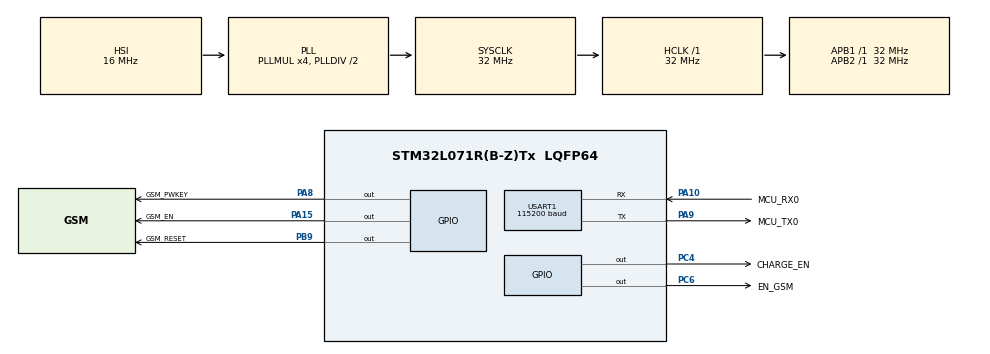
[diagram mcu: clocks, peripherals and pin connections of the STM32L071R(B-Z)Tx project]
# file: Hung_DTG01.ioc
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Mcu.Family=STM32L0
Mcu.Name=STM32L071R(B-Z)Tx
Mcu.Package=LQFP64
NVIC.USART1_IRQn=true\:1\:0\:true\:false\:true\:true\:true
PA10.GPIO_Label=MCU_RX0
PA10.Mode=Asynchronous
PA10.Signal=USART1_RX
PA13.Mode=Serial_Wire
PA13.Signal=SYS_SWDIO
PA14.Mode=Serial_Wire
PA14.Signal=SYS_SWCLK
PA15.GPIO_Label=GSM_EN
PA15.Signal=GPIO_Output
PA8.GPIO_Label=GSM_PWKEY
PA8.Signal=GPIO_Output
PA9.GPIO_Label=MCU_TX0
PA9.Mode=Asynchronous
PA9.Signal=USART1_TX
PB9.GPIO_Label=GSM_RESET
PB9.Signal=GPIO_Output
PC4.GPIO_Label=CHARGE_EN
PC4.Signal=GPIO_Output
PC6.GPIO_Label=EN_GSM
PC6.Signal=GPIO_Output
PH0-OSC_IN.Mode=HSE-External-Oscillator
PH0-OSC_IN.Signal=RCC_OSC_IN
PH1-OSC_OUT.Mode=HSE-External-Oscillator
PH1-OSC_OUT.Signal=RCC_OSC_OUT
ProjectManager.HeapSize=0x200
ProjectManager.StackSize=0x400
ProjectManager.TargetToolchain=STM32CubeIDE
RCC.AHBFreq_Value=32000000
RCC.APB1Freq_Value=32000000
RCC.APB1TimFreq_Value=32000000
RCC.APB2Freq_Value=32000000
RCC.APB2TimFreq_Value=32000000
RCC.HCLKFreq_Value=32000000
RCC.HSE_VALUE=8000000
RCC.HSI16_VALUE=16000000
RCC.HSI_VALUE=16000000
RCC.LSE_VALUE=32768
RCC.MSI_VALUE=2097000
RCC.PLLMUL=RCC_PLLMUL_4
RCC.SYSCLKFreq_VALUE=32000000
RCC.SYSCLKSource=RCC_SYSCLKSOURCE_PLLCLK
RCC.VCOOutputFreq_Value=64000000
USART1.BaudRate=115200
USART1.VirtualMode-Asynchronous=VM_ASYNC
board=custom

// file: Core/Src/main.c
/* USER CODE BEGIN Header */
/**
  ******************************************************************************
  * @file           : main.c
  * @brief          : Main program body
  ******************************************************************************
  * @attention
  *
  * <h2><center>&copy; Copyright (c) 2022 STMicroelectronics.
  * All rights reserved.</center></h2>
  *
  * This software component is licensed by ST under BSD 3-Clause license,
  * the "License"; You may not use this file except in compliance with the
  * License. You may obtain a copy of the License at:
  *                        opensource.org/licenses/BSD-3-Clause
  *
  ******************************************************************************
  */
/* USER CODE END Header */
#include "main.h"
#include "usart.h"
#include "gpio.h"

/* USER CODE BEGIN Includes */
#include "App_Main.h"
/* USER CODE END Includes */

void SystemClock_Config(void);

/* USER CODE BEGIN 0 */

/**
TODO: Implement Expected Response
*/

/* USER CODE END 0 */

int main(void)
{

  /* MCU Configuration--------------------------------------------------------*/

  /* Reset of all peripherals, Initializes the Flash interface and the Systick. */
  HAL_Init();

  /* Configure the system clock */
  SystemClock_Config();

  /* Initialize all configured peripherals */
  MX_GPIO_Init();
  MX_USART1_UART_Init();

  /* Infinite loop */
  while (1)
  {

    /* USER CODE BEGIN 3 */
	  App_Main();
  }
  /* USER CODE END 3 */
}

void SystemClock_Config(void)
{
  RCC_OscInitTypeDef RCC_OscInitStruct = {0};
  RCC_ClkInitTypeDef RCC_ClkInitStruct = {0};
  RCC_PeriphCLKInitTypeDef PeriphClkInit = {0};

  /** Configure the main internal regulator output voltage
  */
  __HAL_PWR_VOLTAGESCALING_CONFIG(PWR_REGULATOR_VOLTAGE_SCALE1);
  /** Initializes the RCC Oscillators according to the specified parameters
  * in the RCC_OscInitTypeDef structure.
  */
  RCC_OscInitStruct.OscillatorType = RCC_OSCILLATORTYPE_HSI;
  RCC_OscInitStruct.HSIState = RCC_HSI_ON;
  RCC_OscInitStruct.HSICalibrationValue = RCC_HSICALIBRATION_DEFAULT;
  RCC_OscInitStruct.PLL.PLLState = RCC_PLL_ON;
  RCC_OscInitStruct.PLL.PLLSource = RCC_PLLSOURCE_HSI;
  RCC_OscInitStruct.PLL.PLLMUL = RCC_PLLMUL_4;
  RCC_OscInitStruct.PLL.PLLDIV = RCC_PLLDIV_2;
  if (HAL_RCC_OscConfig(&RCC_OscInitStruct) != HAL_OK)
  {
    Error_Handler();
  }
  /** Initializes the CPU, AHB and APB buses clocks
  */
  RCC_ClkInitStruct.ClockType = RCC_CLOCKTYPE_HCLK|RCC_CLOCKTYPE_SYSCLK
                              |RCC_CLOCKTYPE_PCLK1|RCC_CLOCKTYPE_PCLK2;
  RCC_ClkInitStruct.SYSCLKSource = RCC_SYSCLKSOURCE_PLLCLK;
  RCC_ClkInitStruct.AHBCLKDivider = RCC_SYSCLK_DIV1;
  RCC_ClkInitStruct.APB1CLKDivider = RCC_HCLK_DIV1;
  RCC_ClkInitStruct.APB2CLKDivider = RCC_HCLK_DIV1;

  if (HAL_RCC_ClockConfig(&RCC_ClkInitStruct, FLASH_LATENCY_1) != HAL_OK)
  {
    Error_Handler();
  }
  PeriphClkInit.PeriphClockSelection = RCC_PERIPHCLK_USART1;
  PeriphClkInit.Usart1ClockSelection = RCC_USART1CLKSOURCE_PCLK2;
  if (HAL_RCCEx_PeriphCLKConfig(&PeriphClkInit) != HAL_OK)
  {
    Error_Handler();
  }
}

void Error_Handler(void)
{
  __disable_irq();
  while (1)
  {
  }
}

/************************ (C) COPYRIGHT STMicroelectronics *****END OF FILE****/
